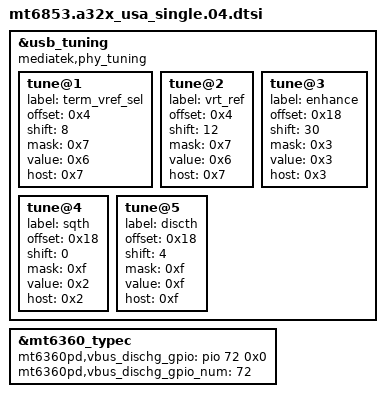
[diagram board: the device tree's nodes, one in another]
/*
 * Generated by Samsung
 * If these files should be changed, then please make a sync with MTK
*/

#include "../../mediatek/k6853v1_64_titan/gpio04_usa.dtsi"
#include "mt6853-a32x_common.dtsi"
#include "mt6853-a32x_camera_03.dtsi"
#include "mt6853-a32x_gripsensor_00.dtsi"
#include "mt6853_input_a32x_05.dtsi"
#include "display_lcd_a32xu_common.dtsi"

&usb_tuning {
	compatible = "mediatek,phy_tuning";

	tune@1 {
		label = "term_vref_sel";
		offset = <0x4>;
		shift = <8>;
		mask = <0x7>;
		value = <0x6>;
		host = <0x7>;
	};

	tune@2 {
		label = "vrt_ref";
		offset = <0x4>;
		shift = <12>;
		mask = <0x7>;
		value = <0x6>;
		host = <0x7>;
	};

	tune@3 {
		label = "enhance";
		offset = <0x18>;
		shift = <30>;
		mask = <0x3>;
		value = <0x3>;
		host = <0x3>;
	};

	tune@4 {
		label = "sqth";
		offset = <0x18>;
		shift = <0>;
		mask = <0xf>;
		value = <0x2>;
		host = <0x2>;
	};

	tune@5 {
		label = "discth";
		offset = <0x18>;
		shift = <4>;
		mask = <0xf>;
		value = <0xf>;
		host = <0xf>;
	};
};

&mt6360_typec {
	mt6360pd,vbus_dischg_gpio = <&pio 72 0x0>;
	mt6360pd,vbus_dischg_gpio_num = <72>;
};
/*End of this file, DO NOT ADD ANYTHING HERE*/
